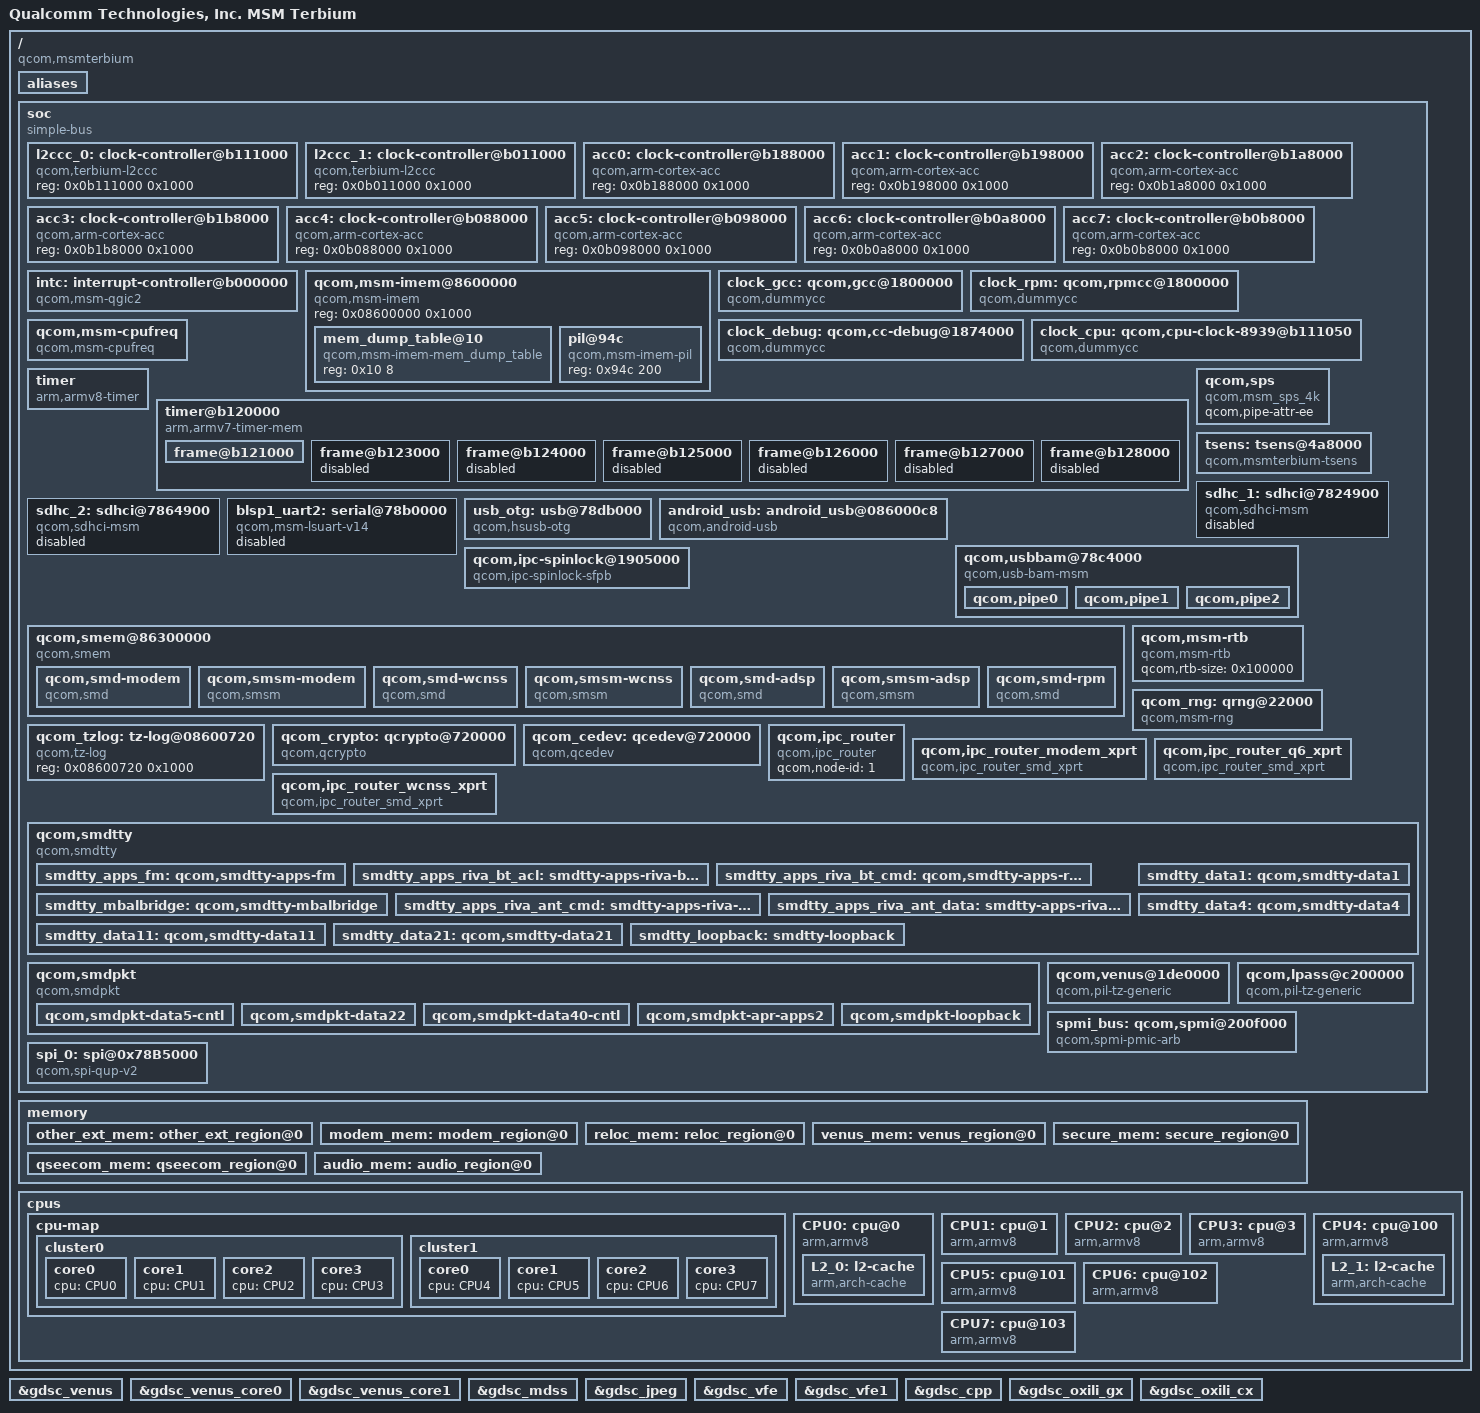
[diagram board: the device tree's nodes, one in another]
/*
 * Copyright (c) 2014-2015, The Linux Foundation. All rights reserved.
 *
 * This program is free software; you can redistribute it and/or modify
 * it under the terms of the GNU General Public License version 2 and
 * only version 2 as published by the Free Software Foundation.
 *
 * This program is distributed in the hope that it will be useful,
 * but WITHOUT ANY WARRANTY; without even the implied warranty of
 * MERCHANTABILITY or FITNESS FOR A PARTICULAR PURPOSE.  See the
 * GNU General Public License for more details.
 */

#include "skeleton64.dtsi"
#include <dt-bindings/clock/msm-clocks-8952.h>

/ {
	model = "Qualcomm Technologies, Inc. MSM Terbium";
	compatible = "qcom,msmterbium";
	qcom,msm-id = <266 0x0>; /* Needs update */
	interrupt-parent = <&intc>;

	aliases {
		/* smdtty devices */
		smd1 = &smdtty_apps_fm;
		smd2 = &smdtty_apps_riva_bt_acl;
		smd3 = &smdtty_apps_riva_bt_cmd;
		smd4 = &smdtty_mbalbridge;
		smd5 = &smdtty_apps_riva_ant_cmd;
		smd6 = &smdtty_apps_riva_ant_data;
		smd7 = &smdtty_data1;
		smd8 = &smdtty_data4;
		smd11 = &smdtty_data11;
		smd21 = &smdtty_data21;
		smd36 = &smdtty_loopback;
	};

	soc: soc { };

	aliases {
		sdhc1 = &sdhc_1; /* SDC1 eMMC slot */
		sdhc2 = &sdhc_2; /* SDC2 SD card slot */
		spi0 = &spi_0;
	};

	memory {
		#address-cells = <2>;
		#size-cells = <2>;

		other_ext_mem: other_ext_region@0 {
			linux,reserve-contiguous-region;
			linux,reserve-region;
			linux,remove-completely;
			reg = <0x0 0x86000000 0x0 0x0800000>;
			label = "other_ext_mem";
		};

		modem_mem: modem_region@0 {
			linux,reserve-contiguous-region;
			linux,reserve-region;
			linux,remove-completely;
			reg = <0x0 0x86800000 0x0 0x05500000>;
			label = "modem_mem";
		};

		reloc_mem: reloc_region@0 {
			linux,reserve-contiguous-region;
			linux,reserve-region;
			linux,remove-completely;
			reg = <0x0 0x8bd00000 0x0 0x1b00000>;
			label = "reloc_mem";
		};

		venus_mem: venus_region@0 {
			linux,reserve-contiguous-region;
			linux,memory-limit = <0x90000000>;
			reg = <0x0 0x0 0x0 0x0500000>;
			label = "venus_mem";
		};

		secure_mem: secure_region@0 {
			linux,reserve-contiguous-region;
			reg = <0x0 0x0 0x0 0x6D00000>;
			label = "secure_mem";
		};

		qseecom_mem: qseecom_region@0 {
			linux,reserve-contiguous-region;
			reg = <0x0 0x0 0x0 0x1000000>;
			label = "qseecom_mem";
		};

		audio_mem: audio_region@0 {
			linux,reserve-contiguous-region;
			reg = <0x0 0x0 0x0 0x314000>;
		};
	};

	cpus {
		#address-cells = <1>;
		#size-cells = <0>;
		cpu-map {
			cluster0 {
				core0 {
					cpu = <&CPU0>;
				};
				core1 {
					cpu = <&CPU1>;
				};
				core2 {
					cpu = <&CPU2>;
				};
				core3 {
					cpu = <&CPU3>;
				};
			};

			cluster1 {
				core0 {
					cpu = <&CPU4>;
				};
				core1 {
					cpu = <&CPU5>;
				};
				core2 {
					cpu = <&CPU6>;
				};
				core3 {
					cpu = <&CPU7>;
				};
			};
		};

		CPU0: cpu@0 {
			device_type = "cpu";
			compatible = "arm,armv8";
			reg = <0x0>;
			enable-method = "qcom,terbium-arm-cortex-acc";
			qcom,acc = <&acc0>;
			next-level-cache = <&L2_0>;
			L2_0: l2-cache {
			      compatible = "arm,arch-cache";
			      cache-level = <2>;
			      power-domain = <&l2ccc_0>;
			};
		};

		CPU1: cpu@1 {
			device_type = "cpu";
			compatible = "arm,armv8";
			reg = <0x1>;
			enable-method = "qcom,terbium-arm-cortex-acc";
			qcom,acc = <&acc1>;
			next-level-cache = <&L2_0>;
		};

		CPU2: cpu@2 {
			device_type = "cpu";
			compatible = "arm,armv8";
			reg = <0x2>;
			enable-method = "qcom,terbium-arm-cortex-acc";
			qcom,acc = <&acc2>;
			next-level-cache = <&L2_0>;
		};

		CPU3: cpu@3 {
			device_type = "cpu";
			compatible = "arm,armv8";
			reg = <0x3>;
			enable-method = "qcom,terbium-arm-cortex-acc";
			qcom,acc = <&acc3>;
			next-level-cache = <&L2_0>;
		};

		CPU4: cpu@100 {
			device_type = "cpu";
			compatible = "arm,armv8";
			reg = <0x100>;
			enable-method = "qcom,terbium-arm-cortex-acc";
			qcom,acc = <&acc4>;
			next-level-cache = <&L2_1>;
			L2_1: l2-cache {
			      compatible = "arm,arch-cache";
			      cache-level = <2>;
			      power-domain = <&l2ccc_1>;
			      };
			};

		CPU5: cpu@101 {
			device_type = "cpu";
			compatible = "arm,armv8";
			reg = <0x101>;
			enable-method = "qcom,terbium-arm-cortex-acc";
			qcom,acc = <&acc5>;
			next-level-cache = <&L2_1>;
		};

		CPU6: cpu@102 {
			device_type = "cpu";
			compatible = "arm,armv8";
			reg = <0x102>;
			enable-method = "qcom,terbium-arm-cortex-acc";
			qcom,acc = <&acc6>;
			next-level-cache = <&L2_1>;
		};

		CPU7: cpu@103 {
			device_type = "cpu";
			compatible = "arm,armv8";
			reg = <0x103>;
			enable-method = "qcom,terbium-arm-cortex-acc";
			qcom,acc = <&acc7>;
			next-level-cache = <&L2_1>;
		};
	};
};

#include "msmterbium-pinctrl.dtsi"
#include "msmterbium-ion.dtsi"
#include "msmterbium-iommu.dtsi"
#include "msmterbium-smp2p.dtsi"

&soc {
	#address-cells = <1>;
	#size-cells = <1>;
	ranges = <0 0 0 0xffffffff>;
	compatible = "simple-bus";

	l2ccc_0: clock-controller@b111000 {
		compatible = "qcom,terbium-l2ccc";
		reg = <0x0b111000 0x1000>;
	};

	l2ccc_1: clock-controller@b011000 {
		compatible = "qcom,terbium-l2ccc";
		reg = <0x0b011000 0x1000>;
	};

	acc0:clock-controller@b188000 {
		compatible = "qcom,arm-cortex-acc";
		reg = <0x0b188000 0x1000>;
	};

	acc1:clock-controller@b198000 {
		compatible = "qcom,arm-cortex-acc";
		reg = <0x0b198000 0x1000>;
	};

	acc2:clock-controller@b1a8000 {
		compatible = "qcom,arm-cortex-acc";
		reg = <0x0b1a8000 0x1000>;
	};

	acc3:clock-controller@b1b8000 {
		compatible = "qcom,arm-cortex-acc";
		reg = <0x0b1b8000 0x1000>;
	};

	acc4:clock-controller@b088000 {
		compatible = "qcom,arm-cortex-acc";
		reg = <0x0b088000 0x1000>;
	};

	acc5:clock-controller@b098000 {
		compatible = "qcom,arm-cortex-acc";
		reg = <0x0b098000 0x1000>;
	};

	acc6:clock-controller@b0a8000 {
		compatible = "qcom,arm-cortex-acc";
		reg = <0x0b0a8000 0x1000>;
	};

	acc7:clock-controller@b0b8000 {
		compatible = "qcom,arm-cortex-acc";
		reg = <0x0b0b8000 0x1000>;
	};

	intc: interrupt-controller@b000000 {
		compatible = "qcom,msm-qgic2";
		interrupt-controller;
		#interrupt-cells = <3>;
		reg = <0x0b000000 0x1000>,
		      <0x0b002000 0x1000>;
	};

	qcom,msm-imem@8600000 {
		compatible = "qcom,msm-imem";
		reg = <0x08600000 0x1000>; /* Address and size of IMEM */
		ranges = <0x0 0x08600000 0x1000>;
		#address-cells = <1>;
		#size-cells = <1>;

		mem_dump_table@10 {
			compatible = "qcom,msm-imem-mem_dump_table";
			reg = <0x10 8>;
		};

		pil@94c {
			compatible = "qcom,msm-imem-pil";
			reg = <0x94c 200>;
		};
	};

	clock_gcc: qcom,gcc@1800000 {
		compatible = "qcom,dummycc";
		#clock-cells = <1>;
	};

	clock_rpm: qcom,rpmcc@1800000 {
		compatible = "qcom,dummycc";
		#clock-cells = <1>;
	};

	clock_debug: qcom,cc-debug@1874000 {
		compatible = "qcom,dummycc";
		#clock-cells = <1>;
	};

	clock_cpu: qcom,cpu-clock-8939@b111050 {
		compatible = "qcom,dummycc";
		#clock-cells = <1>;
	};

	qcom,msm-cpufreq {
		compatible = "qcom,msm-cpufreq";
		clock-names = "l2_clk", "cpu0_clk", "cpu1_clk", "cpu2_clk",
				"cpu3_clk", "cpu4_clk", "cpu5_clk",
				"cpu6_clk", "cpu7_clk";
		clocks = <&clock_cpu clk_a53ssmux_cci>,
			 <&clock_cpu clk_a53ssmux_bc>,
			 <&clock_cpu clk_a53ssmux_bc>,
			 <&clock_cpu clk_a53ssmux_bc>,
			 <&clock_cpu clk_a53ssmux_bc>,
			 <&clock_cpu clk_a53ssmux_lc>,
			 <&clock_cpu clk_a53ssmux_lc>,
			 <&clock_cpu clk_a53ssmux_lc>,
			 <&clock_cpu clk_a53ssmux_lc>;

		qcom,cpufreq-table-0 =
			 <  200000 >,
			 <  345600 >,
			 <  400000 >,
			 <  533330 >,
			 <  800000 >;
		qcom,cpufreq-table-4 =
			 <  200000 >,
			 <  249600 >,
			 <  499200 >,
			 <  800000 >;
	};

	timer {
		compatible = "arm,armv8-timer";
		interrupts = <1 2 0xff08>,
			     <1 3 0xff08>,
			     <1 4 0xff08>,
			     <1 1 0xff08>;
		clock-frequency = <19200000>;
	};

	timer@b120000 {
		#address-cells = <1>;
		#size-cells = <1>;
		ranges;
		compatible = "arm,armv7-timer-mem";
		reg = <0xb120000 0x1000>;
		clock-frequency = <19200000>;

		frame@b121000 {
			frame-number = <0>;
			interrupts = <0 8 0x4>,
				     <0 7 0x4>;
			reg = <0xb121000 0x1000>,
			      <0xb122000 0x1000>;
		};

		frame@b123000 {
			frame-number = <1>;
			interrupts = <0 9 0x4>;
			reg = <0xb123000 0x1000>;
			status = "disabled";
		};

		frame@b124000 {
			frame-number = <2>;
			interrupts = <0 10 0x4>;
			reg = <0xb124000 0x1000>;
			status = "disabled";
		};

		frame@b125000 {
			frame-number = <3>;
			interrupts = <0 11 0x4>;
			reg = <0xb125000 0x1000>;
			status = "disabled";
		};

		frame@b126000 {
			frame-number = <4>;
			interrupts = <0 12 0x4>;
			reg = <0xb126000 0x1000>;
			status = "disabled";
		};

		frame@b127000 {
			frame-number = <5>;
			interrupts = <0 13 0x4>;
			reg = <0xb127000 0x1000>;
			status = "disabled";
		};

		frame@b128000 {
			frame-number = <6>;
			interrupts = <0 14 0x4>;
			reg = <0xb128000 0x1000>;
			status = "disabled";
		};
	};

	qcom,sps {
		compatible = "qcom,msm_sps_4k";
		qcom,pipe-attr-ee;
	};

	tsens: tsens@4a8000 {
		compatible = "qcom,msmterbium-tsens";
		reg = <0x4a8000 0x2000>,
		      <0xa4000  0x1000>;
		reg-names = "tsens_physical", "tsens_eeprom_physical";
		interrupts = <0 184 0>;
		interrupt-names = "tsens-upper-lower";
		qcom,sensors = <11>;
		qcom,slope = <3200 3200 3200 3200 3200 3200 3200 3200 3200 3200 3200>;
		qcom,sensor-id = <0 1 2 3 4 5 6 7 8 9 10>;
		qcom,tsens_base_info = <2 8>;
		qcom,tsens_base_mask = <0 0x218 0xff 0 8>,
				       <1 0x220 0xff 0 8>;
		qcom,tsens_calib_mask = <0 0x228 0x3 0 3>;
		qcom,tsens_sensor_point_bit_size = <6>;
		qcom,tsens_sensor_point1_total_masks = <12>;
		qcom,tsens_sensor_point1 = <0 0x218 0x00003f00 0x8 6>,
					   <1 0x218 0x03f00000 0x14 6>,
					   <2 0x21c 0x0000003f 0x0 6>,
					   <3 0x21c 0x0003f000 0xc 6>,
					   <4 0x220 0x00003f00 0x8 6>,
					   <5 0x220 0x03f00000 0x14 6>,
					   <6 0x224 0x0000003f 0x0 6>,
					   <7 0x224 0x0003f000 0xc 6>,
					   <8 0x228 0x000001f8 0x3 6>,
					   <9 0x228 0x001f8000 0xf 6>,
					   <10 0x228 0xf8000000 0x1b 5>,
					   <10 0x22c 0x00000001 0x0 1>;
		qcom,tsens_sensor_point2_total_masks = <11>;
		qcom,tsens_sensor_point2 = <0 0x218 0x000fc000 0xe 6>,
					   <1 0x218 0xfc000000 0x1a 6>,
					   <2 0x21c 0x00000fc0 0x6 6>,
					   <3 0x21c 0x00fc0000 0x12 6>,
					   <4 0x220 0x000fc000 0xe 6>,
					   <5 0x220 0xfc000000 0x1a 6>,
					   <6 0x224 0x00000fc0 0x6 6>,
					   <7 0x224 0x00fc0000 0x12 6>,
					   <8 0x228 0x00007e00 0x9 6>,
					   <9 0x228 0x07e00000 0x15 6>,
					   <10 0x22c 0x0000007e 0x1 6>;
	};

	sdhc_1: sdhci@7824900 {
		compatible = "qcom,sdhci-msm";
		reg = <0x7824900 0x11c>, <0x7824000 0x800>;
		reg-names = "hc_mem", "core_mem";

		interrupts = <0 123 0>, <0 138 0>;
		interrupt-names = "hc_irq", "pwr_irq";

		qcom,bus-width = <8>;

		qcom,cpu-dma-latency-us = <701>;
		clocks = <&clock_gcc clk_gcc_sdcc1_ahb_clk>,
			 <&clock_gcc clk_gcc_sdcc1_apps_clk>;
		clock-names = "iface_clk", "core_clk";

		status = "disabled";
	};

	sdhc_2: sdhci@7864900 {
		compatible = "qcom,sdhci-msm";
		reg = <0x7864900 0x11c>, <0x7864000 0x800>;
		reg-names = "hc_mem", "core_mem";

		interrupts = <0 125 0>, <0 221 0>;
		interrupt-names = "hc_irq", "pwr_irq";

		qcom,bus-width = <4>;

		qcom,cpu-dma-latency-us = <701>;
		clocks = <&clock_gcc clk_gcc_sdcc2_ahb_clk>,
			 <&clock_gcc clk_gcc_sdcc2_apps_clk>;
		clock-names = "iface_clk", "core_clk";

		qcom,clk-rates = <400000 25000000 50000000 100000000 200000000>;

		status = "disabled";
	};

	blsp1_uart2: serial@78b0000 {
		compatible = "qcom,msm-lsuart-v14";
		reg = <0x78b0000 0x200>;
		interrupts = <0 108 0>;
		status = "disabled";
		clock-names = "core_clk", "iface_clk";
		clocks = <&clock_gcc clk_gcc_blsp1_uart2_apps_clk>,
		       <&clock_gcc clk_gcc_blsp1_ahb_clk>;
	};

	usb_otg: usb@78db000 {
		compatible = "qcom,hsusb-otg";
		reg = <0x78db000 0x400>, <0x6c000 0x200>;
		reg-names = "core", "phy_csr";

		interrupts = <0 134 0>, <0 140 0>;
		interrupt-names = "core_irq", "async_irq";

		hsusb_vdd_dig-supply = <&pmterbium_s6_corner>;
		HSUSB_1p8-supply = <&pmterbium_l7>;
		HSUSB_3p3-supply = <&pmterbium_l13>;
		qcom,vdd-voltage-level = <1 5 7>;

		qcom,hsusb-otg-phy-type = <3>; /* SNPS Femto PHY */
		qcom,hsusb-otg-mode = <1>; /* DEVICE only */
		qcom,hsusb-otg-otg-control = <2>; /* PMIC */
		qcom,dp-manual-pullup;
		qcom,hsusb-otg-disable-reset;
		qcom,hsusb-otg-mpm-dpsehv-int = <49>;
		qcom,hsusb-otg-mpm-dmsehv-int = <58>;
		qcom,boost-sysclk-with-streaming;

		qcom,msm-bus,name = "usb2";
		qcom,msm-bus,num-cases = <3>;
		qcom,msm-bus,num-paths = <1>;
		qcom,msm-bus,vectors-KBps =
				<87 512 0 0>,
				<87 512 80000 0>,
				<87 512 6000  6000>;

		clocks = <&clock_gcc clk_gcc_usb_hs_ahb_clk>,
			 <&clock_gcc clk_gcc_usb_hs_system_clk>,
			 <&clock_gcc clk_gcc_usb2a_phy_sleep_clk>,
			 <&clock_rpm clk_bimc_usb_a_clk>,
			 <&clock_rpm clk_snoc_usb_a_clk>,
			 <&clock_rpm clk_pnoc_usb_a_clk>,
			 <&clock_gcc clk_gcc_qusb2_phy_clk>,
			 <&clock_gcc clk_gcc_usb2_hs_phy_only_clk>,
			 <&clock_gcc clk_gcc_usb_hs_phy_cfg_ahb_clk>,
			 <&clock_rpm clk_xo_otg_clk>;
		clock-names = "iface_clk", "core_clk", "sleep_clk",
				"bimc_clk", "snoc_clk", "pcnoc_clk",
				"phy_reset_clk", "phy_por_clk", "phy_csr_clk",
				"xo";
		qcom,bus-clk-rate = <320000000 200000000 100000000>;
		qcom,max-nominal-sysclk-rate = <133330000>;
	};

	android_usb: android_usb@086000c8 {
		compatible = "qcom,android-usb";
		reg = <0x086000c8 0xc8>;
		qcom,pm-qos-latency = <2 1001 12701>;
		qcom,android-usb-uicc-nluns = /bits/ 8 <1>;
	};

	qcom,usbbam@78c4000 {
		compatible = "qcom,usb-bam-msm";
		reg = <0x78c4000 0x15000>;
		reg-names = "hsusb";
		interrupts = <0 135 0>;
		interrupt-names = "hsusb";
		qcom,usb-bam-num-pipes = <16>;
		qcom,usb-bam-fifo-baseaddr = <0x08606000>;
		qcom,ignore-core-reset-ack;
		qcom,disable-clk-gating;
		qcom,usb-bam-max-mbps-highspeed = <400>;

		qcom,pipe0 {
			label = "hsusb-ipa-out-0";
			qcom,usb-bam-mem-type = <2>;
			qcom,bam-type = <1>;
			qcom,dir = <0>;
			qcom,pipe-num = <0>;
			qcom,peer-bam = <2>;
			qcom,src-bam-physical-address = <0x78c4000>;
			qcom,src-bam-pipe-index = <1>;
			qcom,data-fifo-size = <0x8000>;
			qcom,descriptor-fifo-size = <0x2000>;
		};

		qcom,pipe1 {
			label = "hsusb-ipa-in-0";
			qcom,usb-bam-mem-type = <2>;
			qcom,bam-type = <1>;
			qcom,dir = <1>;
			qcom,pipe-num = <0>;
			qcom,peer-bam = <2>;
			qcom,dst-bam-physical-address = <0x78c4000>;
			qcom,dst-bam-pipe-index = <0>;
			qcom,data-fifo-size = <0x8000>;
			qcom,descriptor-fifo-size = <0x2000>;
		};

		qcom,pipe2 {
			label = "hsusb-qdss-in-0";
			qcom,usb-bam-mem-type = <3>;
			qcom,bam-type = <1>;
			qcom,dir = <1>;
			qcom,pipe-num = <0>;
			qcom,peer-bam = <1>;
			qcom,src-bam-physical-address = <0x6084000>;
			qcom,src-bam-pipe-index = <0>;
			qcom,dst-bam-physical-address = <0x78c4000>;
			qcom,dst-bam-pipe-index = <2>;
			qcom,data-fifo-offset = <0x0>;
			qcom,data-fifo-size = <0xe00>;
			qcom,descriptor-fifo-offset = <0xe00>;
			qcom,descriptor-fifo-size = <0x200>;
		};
	};

	qcom,ipc-spinlock@1905000 {
		compatible = "qcom,ipc-spinlock-sfpb";
		reg = <0x1905000 0x8000>;
		qcom,num-locks = <8>;
	};

	qcom,smem@86300000 {
		compatible = "qcom,smem";
		reg = <0x86300000 0x100000>,
			<0x0b011008 0x4>,
			<0x60000 0x8000>,
			<0x193D000 0x8>;
		reg-names = "smem", "irq-reg-base", "aux-mem1", "smem_targ_info_reg";
		qcom,mpu-enabled;

		qcom,smd-modem {
			compatible = "qcom,smd";
			qcom,smd-edge = <0>;
			qcom,smd-irq-offset = <0x0>;
			qcom,smd-irq-bitmask = <0x1000>;
			interrupts = <0 25 1>;
			label = "modem";
		};

		qcom,smsm-modem {
			compatible = "qcom,smsm";
			qcom,smsm-edge = <0>;
			qcom,smsm-irq-offset = <0x0>;
			qcom,smsm-irq-bitmask = <0x2000>;
			interrupts = <0 26 1>;
		};

		qcom,smd-wcnss {
			compatible = "qcom,smd";
			qcom,smd-edge = <6>;
			qcom,smd-irq-offset = <0x0>;
			qcom,smd-irq-bitmask = <0x20000>;
			interrupts = <0 142 1>;
			label = "wcnss";
		};

		qcom,smsm-wcnss {
			compatible = "qcom,smsm";
			qcom,smsm-edge = <6>;
			qcom,smsm-irq-offset = <0x0>;
			qcom,smsm-irq-bitmask = <0x80000>;
			interrupts = <0 144 1>;
		};

		qcom,smd-adsp {
			compatible = "qcom,smd";
			qcom,smd-edge = <1>;
			qcom,smd-irq-offset = <0x0>;
			qcom,smd-irq-bitmask = <0x100>;
			interrupts = <0 289 1>;
			label = "adsp";
		};

		qcom,smsm-adsp {
			compatible = "qcom,smsm";
			qcom,smsm-edge = <1>;
			qcom,smsm-irq-offset = <0x0>;
			qcom,smsm-irq-bitmask = <0x200>;
			interrupts = <0 290 1>;
		};

		qcom,smd-rpm {
			compatible = "qcom,smd";
			qcom,smd-edge = <15>;
			qcom,smd-irq-offset = <0x0>;
			qcom,smd-irq-bitmask = <0x1>;
			interrupts = <0 168 1>;
			label = "rpm";
			qcom,irq-no-suspend;
			qcom,not-loadable;
		};
	};

	qcom,msm-rtb {
		compatible = "qcom,msm-rtb";
		qcom,rtb-size = <0x100000>; /* 1M EBI1 buffer */
	};

	qcom,msm-imem@8600000 {
		compatible = "qcom,msm-imem";
		reg = <0x08600000 0x1000>; /* Address and size of IMEM */
		ranges = <0x0 0x08600000 0x1000>;
		#address-cells = <1>;
		#size-cells = <1>;

		mem_dump_table@10 {
			compatible = "qcom,msm-imem-mem_dump_table";
			reg = <0x10 8>;
		};
	};

	qcom_rng: qrng@22000 {
		compatible = "qcom,msm-rng";
		reg = <0x22000 0x140>;
		qcom,msm-rng-iface-clk;
		qcom,msm-bus,name = "msm-rng-noc";
		qcom,msm-bus,num-cases = <2>;
		qcom,msm-bus,num-paths = <1>;
		qcom,msm-bus,vectors-KBps =
			<1 618 0 0>,            /* No vote */
			<1 618 0 800>;          /* 100 MB/s */
		clocks = <&clock_gcc clk_gcc_prng_ahb_clk>;
		clock-names = "iface_clk";
	};

	qcom_tzlog: tz-log@08600720 {
		compatible = "qcom,tz-log";
		reg = <0x08600720 0x1000>;
	};

	qcom_crypto: qcrypto@720000 {
		compatible = "qcom,qcrypto";
		reg = <0x720000 0x20000>,
		      <0x704000 0x20000>;
		reg-names = "crypto-base","crypto-bam-base";
		interrupts = <0 207 0>;
		qcom,bam-pipe-pair = <2>;
		qcom,ce-hw-instance = <0>;
		qcom,ce-device = <0>;
		qcom,msm-bus,name = "qcrypto-noc";
		qcom,msm-bus,num-cases = <2>;
		qcom,msm-bus,num-paths = <1>;
		qcom,msm-bus,vectors-KBps =
			<55 512 0 0>,
			<55 512 393600 800000>;
		clocks = <&clock_gcc clk_crypto_clk_src>,
			 <&clock_gcc clk_gcc_crypto_clk>,
			 <&clock_gcc clk_gcc_crypto_ahb_clk>,
			 <&clock_gcc clk_gcc_crypto_axi_clk>;
		clock-names = "core_clk_src", "core_clk",
				"iface_clk", "bus_clk";
		qcom,use-sw-aes-cbc-ecb-ctr-algo;
		qcom,use-sw-aes-xts-algo;
		qcom,use-sw-ahash-algo;
		qcom,ce-opp-freq = <100000000>;
	};

	qcom_cedev: qcedev@720000 {
		compatible = "qcom,qcedev";
		reg = <0x720000 0x20000>,
		      <0x704000 0x20000>;
		reg-names = "crypto-base","crypto-bam-base";
		interrupts = <0 207 0>;
		qcom,bam-pipe-pair = <1>;
		qcom,ce-hw-instance = <0>;
		qcom,ce-device = <0>;
		qcom,ce-hw-shared;
		qcom,msm-bus,name = "qcedev-noc";
		qcom,msm-bus,num-cases = <2>;
		qcom,msm-bus,num-paths = <1>;
		qcom,msm-bus,vectors-KBps =
			<55 512 0 0>,
			<55 512 393600 800000>;
		clocks = <&clock_gcc clk_crypto_clk_src>,
			 <&clock_gcc clk_gcc_crypto_clk>,
			 <&clock_gcc clk_gcc_crypto_ahb_clk>,
			 <&clock_gcc clk_gcc_crypto_axi_clk>;
		clock-names = "core_clk_src", "core_clk",
				"iface_clk", "bus_clk";
		qcom,ce-opp-freq = <100000000>;
	};

	qcom,ipc_router {
		compatible = "qcom,ipc_router";
		qcom,node-id = <1>;
	};

	qcom,ipc_router_modem_xprt {
		compatible = "qcom,ipc_router_smd_xprt";
		qcom,ch-name = "IPCRTR";
		qcom,xprt-remote = "modem";
		qcom,xprt-linkid = <1>;
		qcom,xprt-version = <1>;
		qcom,fragmented-data;
	};

	qcom,ipc_router_q6_xprt {
		compatible = "qcom,ipc_router_smd_xprt";
		qcom,ch-name = "IPCRTR";
		qcom,xprt-remote = "adsp";
		qcom,xprt-linkid = <1>;
		qcom,xprt-version = <1>;
		qcom,fragmented-data;
	};

	qcom,ipc_router_wcnss_xprt {
		compatible = "qcom,ipc_router_smd_xprt";
		qcom,ch-name = "IPCRTR";
		qcom,xprt-remote = "wcnss";
		qcom,xprt-linkid = <1>;
		qcom,xprt-version = <1>;
		qcom,fragmented-data;
	};

	qcom,smdtty {
		compatible = "qcom,smdtty";

		smdtty_apps_fm: qcom,smdtty-apps-fm {
			qcom,smdtty-remote = "wcnss";
			qcom,smdtty-port-name = "APPS_FM";
		};

		smdtty_apps_riva_bt_acl: smdtty-apps-riva-bt-acl {
			qcom,smdtty-remote = "wcnss";
			qcom,smdtty-port-name = "APPS_RIVA_BT_ACL";
		};

		smdtty_apps_riva_bt_cmd: qcom,smdtty-apps-riva-bt-cmd {
			qcom,smdtty-remote = "wcnss";
			qcom,smdtty-port-name = "APPS_RIVA_BT_CMD";
		};

		smdtty_mbalbridge: qcom,smdtty-mbalbridge {
			qcom,smdtty-remote = "modem";
			qcom,smdtty-port-name = "MBALBRIDGE";
		};

		smdtty_apps_riva_ant_cmd: smdtty-apps-riva-ant-cmd {
			qcom,smdtty-remote = "wcnss";
			qcom,smdtty-port-name = "APPS_RIVA_ANT_CMD";
		};

		smdtty_apps_riva_ant_data: smdtty-apps-riva-ant-data {
			qcom,smdtty-remote = "wcnss";
			qcom,smdtty-port-name = "APPS_RIVA_ANT_DATA";
		};

		smdtty_data1: qcom,smdtty-data1 {
			qcom,smdtty-remote = "modem";
			qcom,smdtty-port-name = "DATA1";
		};

		smdtty_data4: qcom,smdtty-data4 {
			qcom,smdtty-remote = "modem";
			qcom,smdtty-port-name = "DATA4";
		};

		smdtty_data11: qcom,smdtty-data11 {
			qcom,smdtty-remote = "modem";
			qcom,smdtty-port-name = "DATA11";
		};

		smdtty_data21: qcom,smdtty-data21 {
			qcom,smdtty-remote = "modem";
			qcom,smdtty-port-name = "DATA21";
		};

		smdtty_loopback: smdtty-loopback {
			qcom,smdtty-remote = "modem";
			qcom,smdtty-port-name = "LOOPBACK";
			qcom,smdtty-dev-name = "LOOPBACK_TTY";
		};
	};

	qcom,smdpkt {
		compatible = "qcom,smdpkt";

		qcom,smdpkt-data5-cntl {
			qcom,smdpkt-remote = "modem";
			qcom,smdpkt-port-name = "DATA5_CNTL";
			qcom,smdpkt-dev-name = "smdcntl0";
		};

		qcom,smdpkt-data22 {
			qcom,smdpkt-remote = "modem";
			qcom,smdpkt-port-name = "DATA22";
			qcom,smdpkt-dev-name = "smd22";
		};

		qcom,smdpkt-data40-cntl {
			qcom,smdpkt-remote = "modem";
			qcom,smdpkt-port-name = "DATA40_CNTL";
			qcom,smdpkt-dev-name = "smdcntl8";
		};

		qcom,smdpkt-apr-apps2 {
			qcom,smdpkt-remote = "modem";
			qcom,smdpkt-port-name = "apr_apps2";
			qcom,smdpkt-dev-name = "apr_apps2";
		};

		qcom,smdpkt-loopback {
			qcom,smdpkt-remote = "modem";
			qcom,smdpkt-port-name = "LOOPBACK";
			qcom,smdpkt-dev-name = "smd_pkt_loopback";
		};
	};

	qcom,venus@1de0000 {
		compatible = "qcom,pil-tz-generic";
		reg = <0x1de0000 0x4000>;

		vdd-supply = <&gdsc_venus>;
		qcom,proxy-reg-names = "vdd";

		clocks = <&clock_gcc clk_gcc_venus0_vcodec0_clk>,
			 <&clock_gcc clk_gcc_venus0_ahb_clk>,
			 <&clock_gcc clk_gcc_venus0_axi_clk>,
			 <&clock_gcc clk_gcc_crypto_clk>,
			 <&clock_gcc clk_gcc_crypto_ahb_clk>,
			 <&clock_gcc clk_gcc_crypto_axi_clk>,
			 <&clock_gcc clk_crypto_clk_src>;

		clock-names = "core_clk", "iface_clk", "bus_clk",
				"scm_core_clk", "scm_iface_clk",
				"scm_bus_clk", "scm_core_clk_src";

		qcom,proxy-clock-names = "core_clk", "iface_clk",
					 "bus_clk", "scm_core_clk",
					 "scm_iface_clk", "scm_bus_clk",
					 "scm_core_clk_src";
		qcom,scm_core_clk_src-freq = <80000000>;

		qcom,msm-bus,name = "pil-venus";
		qcom,msm-bus,num-cases = <2>;
		qcom,msm-bus,num-paths = <1>;
		qcom,msm-bus,vectors-KBps =
				<63 512 0 0>,
				<63 512 0 304000>;
		qcom,pas-id = <9>;
		qcom,proxy-timeout-ms = <100>;
		qcom,firmware-name = "venus";
		linux,contiguous-region = <&venus_mem>;
	};

	qcom,lpass@c200000 {
		compatible = "qcom,pil-tz-generic";
		reg = <0xc200000 0x00100>;
		interrupts = <0 293 1>;

		vdd_cx-supply = <&pmterbium_s2_corner>;
		qcom,proxy-reg-names = "vdd_cx";
		qcom,vdd_cx-uV-uA = <7 100000>;

		clocks = <&clock_gcc clk_xo_pil_lpass_clk>,
			 <&clock_gcc clk_gcc_crypto_clk>,
			 <&clock_gcc clk_gcc_crypto_ahb_clk>,
			 <&clock_gcc clk_gcc_crypto_axi_clk>,
			 <&clock_gcc clk_crypto_clk_src>;
		clock-names = "xo", "scm_core_clk", "scm_iface_clk",
				"scm_bus_clk", "scm_core_clk_src";
		qcom,proxy-clock-names = "xo", "scm_core_clk", "scm_iface_clk",
				 "scm_bus_clk", "scm_core_clk_src";
		qcom,scm_core_clk_src-freq = <80000000>;

		qcom,pas-id = <1>;
		qcom,proxy-timeout-ms = <10000>;
		qcom,smem-id = <423>;
		qcom,sysmon-id = <1>;
		qcom,ssctl-instance-id = <0x14>;
		qcom,firmware-name = "adsp";

		/* GPIO inputs from lpass */
		qcom,gpio-err-fatal = <&smp2pgpio_ssr_smp2p_2_in 0 0>;
		qcom,gpio-proxy-unvote = <&smp2pgpio_ssr_smp2p_2_in 2 0>;
		qcom,gpio-err-ready = <&smp2pgpio_ssr_smp2p_2_in 1 0>;
		qcom,gpio-stop-ack = <&smp2pgpio_ssr_smp2p_2_in 3 0>;

		/* GPIO output to lpass */
		qcom,gpio-force-stop = <&smp2pgpio_ssr_smp2p_2_out 0 0>;

		linux,contiguous-region = <&reloc_mem>;
	};

        spmi_bus: qcom,spmi@200f000 {
                compatible = "qcom,spmi-pmic-arb";
                reg = <0x200f000 0x1000>,
                        <0x2400000 0x800000>,
                        <0x2c00000 0x800000>,
                        <0x3800000 0x200000>,
                        <0x200a000 0x2100>;
                reg-names = "core", "chnls", "obsrvr", "intr", "cnfg";
                interrupts = <0 190 0>;
                qcom,pmic-arb-channel = <0>;
                qcom,pmic-arb-max-peripherals = <256>;
                qcom,pmic-arb-max-periph-interrupts = <224>;
                qcom,pmic-arb-ee = <0>;
                #interrupt-cells = <3>;
                interrupt-controller;
                #address-cells = <1>;
                #size-cells = <0>;
                cell-index = <0>;
                qcom,not-wakeup; /* Needed until MPM is fully configured. */
	};

	spi_0: spi@0x78B5000 { /* BLSP1 QUP0 */
		compatible = "qcom,spi-qup-v2";
		reg-names = "spi_physical", "spi_bam_physical";
		reg = <0x78B5000 0x600>,
		      <0x7884000 0x1f000>;
		interrupt-names = "spi_irq", "spi_bam_irq";
		interrupts = <0 95 0>, <0 238 0>;
		spi-max-frequency = <19200000>;
		pinctrl-names = "spi_default", "spi_sleep";
		pinctrl-0 = <&spi0_default &spi0_cs0_active>;
		pinctrl-1 = <&spi0_sleep &spi0_cs0_sleep>;
		clocks = <&clock_gcc clk_gcc_blsp1_ahb_clk>,
			 <&clock_gcc clk_gcc_blsp1_qup1_spi_apps_clk>;
		clock-names = "iface_clk", "core_clk";
		qcom,infinite-mode = <0>;
		qcom,use-bam;
		qcom,use-pinctrl;
		qcom,ver-reg-exists;
		qcom,bam-consumer-pipe-index = <4>;
		qcom,bam-producer-pipe-index = <5>;
		qcom,master-id = <86>;
	};
};

#include "msmterbium-regulator.dtsi"
#include "msm-gdsc-8916.dtsi"
#include "msm-pm8950.dtsi"
#include "msm-pmi8950.dtsi"

&gdsc_venus {
	status = "okay";
};

&gdsc_venus_core0 {
	status = "okay";
};

&gdsc_venus_core1 {
	status = "okay";
};

&gdsc_mdss {
	status = "okay";
};

&gdsc_jpeg {
	status = "okay";
};

&gdsc_vfe {
	status = "okay";
};

&gdsc_vfe1 {
	status = "okay";
};

&gdsc_cpp {
	status = "okay";
};

&gdsc_oxili_gx {
	status = "okay";
};

&gdsc_oxili_cx {
	status = "okay";
};
